VERSION ""

NS_ :

BS_:

BU_: ECM
VAL_TABLE_ light_source_table 1 "user" 0 "car_fade" ;
VAL_TABLE_ audio_status_table 1 "ON" 0 "OFF" ;
VAL_TABLE_ language_table 4 "french" 3 "spanish" 2 "english uk" 1 "english us" 0 "italian" ;
VAL_TABLE_ theme_table 3 "silver theme" 2 "gold theme" 1 "darkblue theme" 0 "darkred theme" ;

BO_ 2316763138 ENVIRONMENT_LIGHT: 2 Vector__XXX
 SG_ right_light_source : 13|2@0+ (1,0) [0|0] "" Vector__XXX
 SG_ left_light_source : 15|2@0+ (1,0) [0|0] "" Vector__XXX
 SG_ right_light_level : 3|8@0+ (1,0) [0|255] "" Vector__XXX
 SG_ left_light_level : 7|8@0+ (1,0) [0|255] "" Vector__XXX

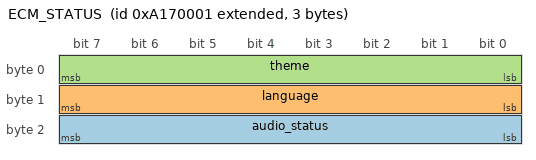
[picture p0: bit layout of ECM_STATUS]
BO_ 2316763137 ECM_STATUS: 3 ECM
 SG_ audio_status : 23|8@0+ (1,0) [0|0] "" Vector__XXX
 SG_ language : 15|8@0+ (1,0) [0|255] "" Vector__XXX
 SG_ theme : 7|8@0+ (1,0) [0|255] "" Vector__XXX

BA_DEF_ BO_  "J1939PgAppearanceOnBus" ENUM  "Default","CAN_Extended","CANFD_Extended";
BA_DEF_ BO_  "J1939CPgSendTimeout" INT -1 3600000;
BA_DEF_ BO_  "J1939CPgTOS" INT 0 7;
BA_DEF_ BU_  "J1939MultiPgSendTimeout" INT 0 3600000;
BA_DEF_ BU_  "J1939MultiPgSizeThreshold" INT 0 64;
BA_DEF_ BU_  "J1939MultiPgBroadcastType" ENUM  "FBFF","FEFF";
BA_DEF_ SG_  "SigType" ENUM  "Default","Range","RangeSigned","ASCII","Discrete","Control","ReferencePGN","DTC","StringDelimiter","StringLength","StringLengthControl","MessageCounter","MessageChecksum";
BA_DEF_ SG_  "GenSigILSupport" ENUM  "No","Yes";
BA_DEF_ SG_  "GenSigSendType" ENUM  "Cyclic","OnWrite","OnWriteWithRepetition","OnChange","OnChangeWithRepetition","IfActive","IfActiveWithRepetition","NoSigSendType";
BA_DEF_ BO_  "GenMsgILSupport" ENUM  "No","Yes";
BA_DEF_ BU_  "NmStationAddress" INT 0 255;
BA_DEF_ BO_  "GenMsgSendType" ENUM  "cyclic","NotUsed","NotUsed","NotUsed","NotUsed","NotUsed","NotUsed","IfActive","noMsgSendType";
BA_DEF_ BO_  "GenMsgRequestable" INT 0 1;
BA_DEF_  "DBName" STRING ;
BA_DEF_  "BusType" STRING ;
BA_DEF_  "ProtocolType" STRING ;
BA_DEF_ BO_  "VFrameFormat" ENUM  "StandardCAN","ExtendedCAN","reserved","J1939PG","reserved","reserved","reserved","reserved","reserved","reserved","reserved","reserved","reserved","reserved","StandardCAN_FD","ExtendedCAN_FD";
BA_DEF_DEF_  "J1939PgAppearanceOnBus" "Default";
BA_DEF_DEF_  "J1939CPgSendTimeout" -1;
BA_DEF_DEF_  "J1939CPgTOS" 2;
BA_DEF_DEF_  "J1939MultiPgSendTimeout" 2;
BA_DEF_DEF_  "J1939MultiPgSizeThreshold" 56;
BA_DEF_DEF_  "J1939MultiPgBroadcastType" "FBFF";
BA_DEF_DEF_  "SigType" "Default";
BA_DEF_DEF_  "GenSigILSupport" "Yes";
BA_DEF_DEF_  "GenSigSendType" "NoSigSendType";
BA_DEF_DEF_  "GenMsgILSupport" "Yes";
BA_DEF_DEF_  "NmStationAddress" 254;
BA_DEF_DEF_  "GenMsgSendType" "noMsgSendType";
BA_DEF_DEF_  "GenMsgRequestable" 1;
BA_DEF_DEF_  "DBName" "";
BA_DEF_DEF_  "BusType" "CAN";
BA_DEF_DEF_  "ProtocolType" "J1939";
BA_DEF_DEF_  "VFrameFormat" "J1939PG";
BA_ "DBName" "ecmBCan";
BA_ "VFrameFormat" BO_ 2316763138 1;
BA_ "VFrameFormat" BO_ 2316763137 1;
VAL_ 2316763138 right_light_source 1 "user" 0 "car_fade" ;
VAL_ 2316763138 left_light_source 1 "user" 0 "car_fade" ;
VAL_ 2316763137 audio_status 1 "ON" 0 "OFF" ;
VAL_ 2316763137 language 4 "french" 3 "spanish" 2 "english uk" 1 "english us" 0 "italian" ;
VAL_ 2316763137 theme 3 "silver theme" 2 "gold theme" 1 "darkblue theme" 0 "darkred theme" ;
